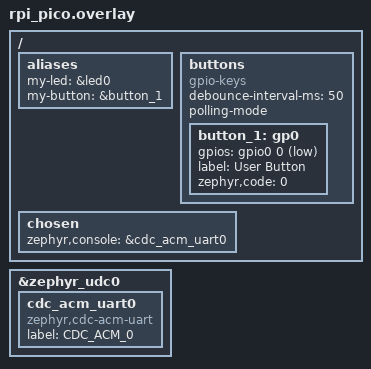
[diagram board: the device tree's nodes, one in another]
/ {
    aliases {
        my-led = &led0;
        my-button = &button_1;
    };

    buttons {
        compatible = "gpio-keys";
        debounce-interval-ms = <50>;
        polling-mode;

        button_1: gp0 {
            gpios = <&gpio0 0 (GPIO_ACTIVE_LOW | GPIO_PULL_UP)>;
            label = "User Button";
            zephyr,code = <0>;
        };
    };

	chosen {
        zephyr,console = &cdc_acm_uart0;
    };
};

&zephyr_udc0 {
    cdc_acm_uart0: cdc_acm_uart0 {
        compatible = "zephyr,cdc-acm-uart";
        label = "CDC_ACM_0";
    };
};
